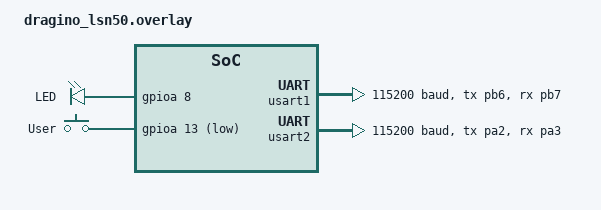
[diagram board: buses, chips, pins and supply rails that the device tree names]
/*
 * Copyright (c) 2018 Endre Karlson <endre.karlson@gmail.com>
 *
 * SPDX-License-Identifier: Apache-2.0
 */

/ {
	chosen {
		zephyr,console = &usart2;
		zephyr,shell-uart = &usart2;
	};

        leds {
                compatible = "gpio-leds";
                led0: led0 {
                        gpios = <&gpioa 8 GPIO_ACTIVE_HIGH>;
                        label = "LED";
                };
        };

	gpio_keys {
                compatible = "gpio-keys";
                user_button: button {
                        label = "User";
                        gpios = <&gpioa 13 GPIO_ACTIVE_LOW>;
                };
        };

        aliases {
                led0 = &led0;
                sw0 = &user_button;
        };
};


&usart1 {
	pinctrl-0 = <&usart1_tx_pb6 &usart1_rx_pb7>;
	current-speed = <115200>;
	status = "okay";
};

&usart2 {
	pinctrl-0 = <&usart2_tx_pa2 &usart2_rx_pa3>;
	current-speed = <115200>;
	status = "okay";
};
